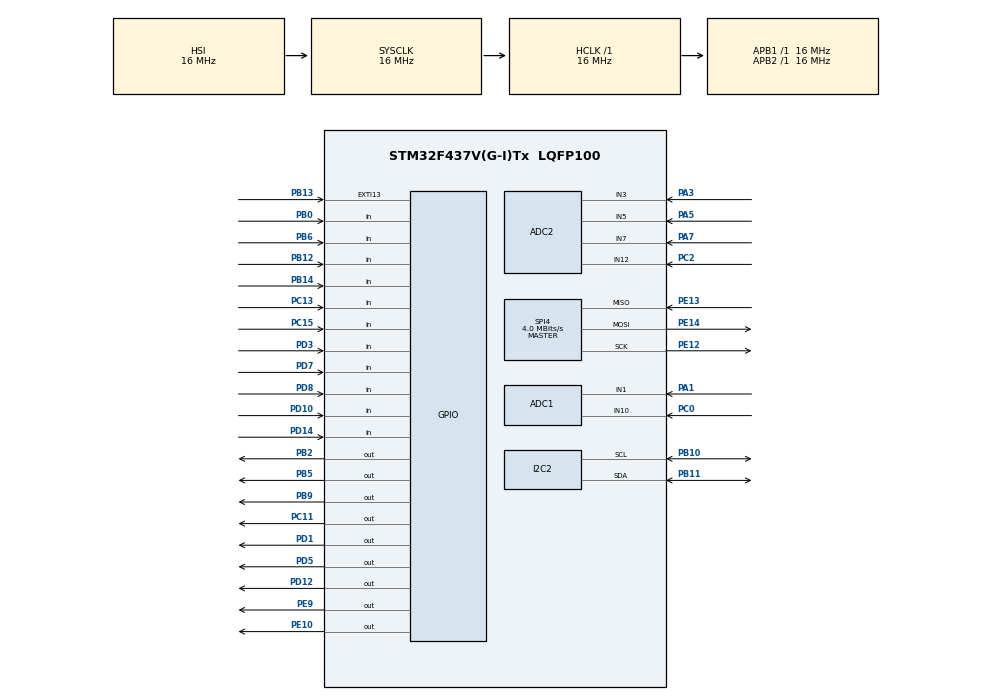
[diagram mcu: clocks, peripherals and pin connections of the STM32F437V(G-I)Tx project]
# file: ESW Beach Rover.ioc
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ADC1.Channel-0\#ChannelRegularConversion=ADC_CHANNEL_1
ADC1.NbrOfConversionFlag=1
ADC1.Rank-0\#ChannelRegularConversion=1
ADC1.SamplingTime-0\#ChannelRegularConversion=ADC_SAMPLETIME_3CYCLES
ADC1.master=1
ADC2.Channel-0\#ChannelRegularConversion=ADC_CHANNEL_3
ADC2.NbrOfConversionFlag=1
ADC2.Rank-0\#ChannelRegularConversion=1
ADC2.SamplingTime-0\#ChannelRegularConversion=ADC_SAMPLETIME_3CYCLES
Mcu.Family=STM32F4
Mcu.Name=STM32F437V(G-I)Tx
Mcu.Package=LQFP100
NVIC.PriorityGroup=NVIC_PRIORITYGROUP_4
PA1.Signal=ADCx_IN1
PA11.Signal=S_TIM1_CH4
PA13.Signal=SYS_JTMS-SWDIO
PA14.Signal=SYS_JTCK-SWCLK
PA15.Signal=S_TIM2_CH1_ETR
PA3.Signal=ADCx_IN3
PA5.Signal=ADCx_IN5
PA7.Signal=ADCx_IN7
PA9.Signal=S_TIM1_CH2
PB0.Signal=GPIO_Input
PB10.Mode=I2C
PB10.Signal=I2C2_SCL
PB11.Mode=I2C
PB11.Signal=I2C2_SDA
PB12.Signal=GPIO_Input
PB13.Signal=GPXTI13
PB14.Signal=GPIO_Input
PB2/BOOT1.Signal=GPIO_Output
PB5.Signal=GPIO_Output
PB6.Signal=GPIO_Input
PB9.Signal=GPIO_Output
PC0.Signal=ADCx_IN10
PC11.Signal=GPIO_Output
PC12.Signal=UART5_TX
PC13.Signal=GPIO_Input
PC15/OSC32_OUT.Signal=GPIO_Input
PC2.Signal=ADCx_IN12
PC6.Signal=S_TIM3_CH1
PC8.Signal=S_TIM3_CH3
PD1.Signal=GPIO_Output
PD10.Signal=GPIO_Input
PD12.Signal=GPIO_Output
PD14.Signal=GPIO_Input
PD2.Signal=UART5_RX
PD3.Signal=GPIO_Input
PD5.Signal=GPIO_Output
PD7.Signal=GPIO_Input
PD8.Signal=GPIO_Input
PE10.Signal=GPIO_Output
PE12.Mode=Full_Duplex_Master
PE12.Signal=SPI4_SCK
PE13.Mode=Full_Duplex_Master
PE13.Signal=SPI4_MISO
PE14.Mode=Full_Duplex_Master
PE14.Signal=SPI4_MOSI
PE9.Signal=GPIO_Output
ProjectManager.HeapSize=0x200
ProjectManager.StackSize=0x400
ProjectManager.TargetToolchain=STM32CubeIDE
RCC.AHBFreq_Value=16000000
RCC.APB1Freq_Value=16000000
RCC.APB2Freq_Value=16000000
RCC.CortexFreq_Value=16000000
RCC.HSE_VALUE=25000000
RCC.HSI_VALUE=16000000
RCC.LSE_VALUE=32768
RCC.SYSCLKFreq_VALUE=16000000
RCC.VCOOutputFreq_Value=192000000
SH.ADCx_IN1.0=ADC1_IN1,IN1
SH.ADCx_IN10.0=ADC1_IN10,IN10
SH.ADCx_IN12.0=ADC2_IN12,IN12
SH.ADCx_IN3.0=ADC2_IN3,IN3
SH.ADCx_IN5.0=ADC2_IN5,IN5
SH.ADCx_IN7.0=ADC2_IN7,IN7
SH.S_TIM1_CH2.0=TIM1_CH2
SH.S_TIM1_CH4.0=TIM1_CH4
SH.S_TIM2_CH1_ETR.0=TIM2_CH1
SH.S_TIM3_CH1.0=TIM3_CH1
SH.S_TIM3_CH3.0=TIM3_CH3
SPI4.BaudRatePrescaler=SPI_BAUDRATEPRESCALER_4
SPI4.CalculateBaudRate=4.0 MBits/s
SPI4.Direction=SPI_DIRECTION_2LINES
SPI4.Mode=SPI_MODE_MASTER
SPI4.VirtualType=VM_MASTER
board=custom

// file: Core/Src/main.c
/* USER CODE BEGIN Header */
/**
  ******************************************************************************
  * @file           : main.c
  * @brief          : Main program body
  ******************************************************************************
  * @attention
  *
  * Copyright (c) 2025 STMicroelectronics.
  * All rights reserved.
  *
  * This software is licensed under terms that can be found in the LICENSE file
  * in the root directory of this software component.
  * If no LICENSE file comes with this software, it is provided AS-IS.
  *
  ******************************************************************************
  */
/* USER CODE END Header */
#include "main.h"

/* USER CODE BEGIN Includes */
#include <string.h>
#include "NRF24.h"
#include "NRF24_reg_addresses.h"
/* USER CODE END Includes */

/* USER CODE BEGIN PD */
#define NRF_CE_HIGH()    HAL_GPIO_WritePin(GPIOE, GPIO_PIN_10, GPIO_PIN_SET);
#define NRF_CE_LOW()     HAL_GPIO_WritePin(GPIOE, GPIO_PIN_10, GPIO_PIN_RESET);

#define NRF_CSN_HIGH()   HAL_GPIO_WritePin(GPIOE, GPIO_PIN_9, GPIO_PIN_SET);
#define NRF_CSN_LOW()    HAL_GPIO_WritePin(GPIOE, GPIO_PIN_9, GPIO_PIN_RESET);

#define PLD_SIZE 32
/* USER CODE END PD */

ADC_HandleTypeDef hadc1;
ADC_HandleTypeDef hadc2;

I2C_HandleTypeDef hi2c2;

SPI_HandleTypeDef hspi4;

void SystemClock_Config(void);
static void MX_GPIO_Init(void);
static void MX_ADC1_Init(void);
static void MX_ADC2_Init(void);
static void MX_I2C2_Init(void);
static void MX_SPI4_Init(void);

int main(void)
{

  /* MCU Configuration--------------------------------------------------------*/

  /* Reset of all peripherals, Initializes the Flash interface and the Systick. */
  HAL_Init();

  /* Configure the system clock */
  SystemClock_Config();

  /* Initialize all configured peripherals */
  MX_GPIO_Init();
  MX_ADC1_Init();
  MX_ADC2_Init();
  MX_I2C2_Init();
  MX_SPI4_Init();

  /* Infinite loop */
  while (1)
  {

  }
}

void SystemClock_Config(void)
{
  RCC_OscInitTypeDef RCC_OscInitStruct = {0};
  RCC_ClkInitTypeDef RCC_ClkInitStruct = {0};

  /** Configure the main internal regulator output voltage
  */
  __HAL_RCC_PWR_CLK_ENABLE();
  __HAL_PWR_VOLTAGESCALING_CONFIG(PWR_REGULATOR_VOLTAGE_SCALE3);

  /** Initializes the RCC Oscillators according to the specified parameters
  * in the RCC_OscInitTypeDef structure.
  */
  RCC_OscInitStruct.OscillatorType = RCC_OSCILLATORTYPE_HSI;
  RCC_OscInitStruct.HSIState = RCC_HSI_ON;
  RCC_OscInitStruct.HSICalibrationValue = RCC_HSICALIBRATION_DEFAULT;
  RCC_OscInitStruct.PLL.PLLState = RCC_PLL_NONE;
  if (HAL_RCC_OscConfig(&RCC_OscInitStruct) != HAL_OK)
  {
    Error_Handler();
  }

  /** Initializes the CPU, AHB and APB buses clocks
  */
  RCC_ClkInitStruct.ClockType = RCC_CLOCKTYPE_HCLK|RCC_CLOCKTYPE_SYSCLK
                              |RCC_CLOCKTYPE_PCLK1|RCC_CLOCKTYPE_PCLK2;
  RCC_ClkInitStruct.SYSCLKSource = RCC_SYSCLKSOURCE_HSI;
  RCC_ClkInitStruct.AHBCLKDivider = RCC_SYSCLK_DIV1;
  RCC_ClkInitStruct.APB1CLKDivider = RCC_HCLK_DIV1;
  RCC_ClkInitStruct.APB2CLKDivider = RCC_HCLK_DIV1;

  if (HAL_RCC_ClockConfig(&RCC_ClkInitStruct, FLASH_LATENCY_0) != HAL_OK)
  {
    Error_Handler();
  }
}

static void MX_ADC1_Init(void)
{

  ADC_ChannelConfTypeDef sConfig = {0};

  /** Configure the global features of the ADC (Clock, Resolution, Data Alignment and number of conversion)
  */
  hadc1.Instance = ADC1;
  hadc1.Init.ClockPrescaler = ADC_CLOCK_SYNC_PCLK_DIV2;
  hadc1.Init.Resolution = ADC_RESOLUTION_12B;
  hadc1.Init.ScanConvMode = DISABLE;
  hadc1.Init.ContinuousConvMode = DISABLE;
  hadc1.Init.DiscontinuousConvMode = DISABLE;
  hadc1.Init.ExternalTrigConvEdge = ADC_EXTERNALTRIGCONVEDGE_NONE;
  hadc1.Init.ExternalTrigConv = ADC_SOFTWARE_START;
  hadc1.Init.DataAlign = ADC_DATAALIGN_RIGHT;
  hadc1.Init.NbrOfConversion = 1;
  hadc1.Init.DMAContinuousRequests = DISABLE;
  hadc1.Init.EOCSelection = ADC_EOC_SINGLE_CONV;
  if (HAL_ADC_Init(&hadc1) != HAL_OK)
  {
    Error_Handler();
  }

  /** Configure for the selected ADC regular channel its corresponding rank in the sequencer and its sample time.
  */
  sConfig.Channel = ADC_CHANNEL_1;
  sConfig.Rank = 1;
  sConfig.SamplingTime = ADC_SAMPLETIME_3CYCLES;
  if (HAL_ADC_ConfigChannel(&hadc1, &sConfig) != HAL_OK)
  {
    Error_Handler();
  }

}

static void MX_ADC2_Init(void)
{

  ADC_ChannelConfTypeDef sConfig = {0};

  /** Configure the global features of the ADC (Clock, Resolution, Data Alignment and number of conversion)
  */
  hadc2.Instance = ADC2;
  hadc2.Init.ClockPrescaler = ADC_CLOCK_SYNC_PCLK_DIV2;
  hadc2.Init.Resolution = ADC_RESOLUTION_12B;
  hadc2.Init.ScanConvMode = DISABLE;
  hadc2.Init.ContinuousConvMode = DISABLE;
  hadc2.Init.DiscontinuousConvMode = DISABLE;
  hadc2.Init.ExternalTrigConvEdge = ADC_EXTERNALTRIGCONVEDGE_NONE;
  hadc2.Init.ExternalTrigConv = ADC_SOFTWARE_START;
  hadc2.Init.DataAlign = ADC_DATAALIGN_RIGHT;
  hadc2.Init.NbrOfConversion = 1;
  hadc2.Init.DMAContinuousRequests = DISABLE;
  hadc2.Init.EOCSelection = ADC_EOC_SINGLE_CONV;
  if (HAL_ADC_Init(&hadc2) != HAL_OK)
  {
    Error_Handler();
  }

  /** Configure for the selected ADC regular channel its corresponding rank in the sequencer and its sample time.
  */
  sConfig.Channel = ADC_CHANNEL_3;
  sConfig.Rank = 1;
  sConfig.SamplingTime = ADC_SAMPLETIME_3CYCLES;
  if (HAL_ADC_ConfigChannel(&hadc2, &sConfig) != HAL_OK)
  {
    Error_Handler();
  }

}

static void MX_I2C2_Init(void)
{

  hi2c2.Instance = I2C2;
  hi2c2.Init.ClockSpeed = 100000;
  hi2c2.Init.DutyCycle = I2C_DUTYCYCLE_2;
  hi2c2.Init.OwnAddress1 = 0;
  hi2c2.Init.AddressingMode = I2C_ADDRESSINGMODE_7BIT;
  hi2c2.Init.DualAddressMode = I2C_DUALADDRESS_DISABLE;
  hi2c2.Init.OwnAddress2 = 0;
  hi2c2.Init.GeneralCallMode = I2C_GENERALCALL_DISABLE;
  hi2c2.Init.NoStretchMode = I2C_NOSTRETCH_DISABLE;
  if (HAL_I2C_Init(&hi2c2) != HAL_OK)
  {
    Error_Handler();
  }

  /** Configure Analogue filter
  */
  if (HAL_I2CEx_ConfigAnalogFilter(&hi2c2, I2C_ANALOGFILTER_ENABLE) != HAL_OK)
  {
    Error_Handler();
  }

  /** Configure Digital filter
  */
  if (HAL_I2CEx_ConfigDigitalFilter(&hi2c2, 0) != HAL_OK)
  {
    Error_Handler();
  }

}

static void MX_SPI4_Init(void)
{

  /* SPI4 parameter configuration*/
  hspi4.Instance = SPI4;
  hspi4.Init.Mode = SPI_MODE_MASTER;
  hspi4.Init.Direction = SPI_DIRECTION_2LINES;
  hspi4.Init.DataSize = SPI_DATASIZE_8BIT;
  hspi4.Init.CLKPolarity = SPI_POLARITY_LOW;
  hspi4.Init.CLKPhase = SPI_PHASE_1EDGE;
  hspi4.Init.NSS = SPI_NSS_SOFT;
  hspi4.Init.BaudRatePrescaler = SPI_BAUDRATEPRESCALER_4;
  hspi4.Init.FirstBit = SPI_FIRSTBIT_MSB;
  hspi4.Init.TIMode = SPI_TIMODE_DISABLE;
  hspi4.Init.CRCCalculation = SPI_CRCCALCULATION_DISABLE;
  hspi4.Init.CRCPolynomial = 10;
  if (HAL_SPI_Init(&hspi4) != HAL_OK)
  {
    Error_Handler();
  }

}

static void MX_GPIO_Init(void)
{
  GPIO_InitTypeDef GPIO_InitStruct = {0};

  /* GPIO Ports Clock Enable */
  __HAL_RCC_GPIOC_CLK_ENABLE();
  __HAL_RCC_GPIOA_CLK_ENABLE();
  __HAL_RCC_GPIOB_CLK_ENABLE();
  __HAL_RCC_GPIOE_CLK_ENABLE();
  __HAL_RCC_GPIOD_CLK_ENABLE();

  /*Configure GPIO pin Output Level */
  HAL_GPIO_WritePin(GPIOB, GPIO_PIN_2|GPIO_PIN_5|GPIO_PIN_9, GPIO_PIN_RESET);

  /*Configure GPIO pin Output Level */
  HAL_GPIO_WritePin(GPIOE, GPIO_PIN_9|GPIO_PIN_10, GPIO_PIN_RESET);

  /*Configure GPIO pin Output Level */
  HAL_GPIO_WritePin(GPIOD, GPIO_PIN_12|GPIO_PIN_1|GPIO_PIN_5, GPIO_PIN_RESET);

  /*Configure GPIO pin Output Level */
  HAL_GPIO_WritePin(GPIOC, GPIO_PIN_11, GPIO_PIN_RESET);

  /*Configure GPIO pins : PC13 PC15 */
  GPIO_InitStruct.Pin = GPIO_PIN_13|GPIO_PIN_15;
  GPIO_InitStruct.Mode = GPIO_MODE_INPUT;
  GPIO_InitStruct.Pull = GPIO_NOPULL;
  HAL_GPIO_Init(GPIOC, &GPIO_InitStruct);

  /*Configure GPIO pins : PB0 PB12 PB13 PB14
                           PB6 */
  GPIO_InitStruct.Pin = GPIO_PIN_0|GPIO_PIN_12|GPIO_PIN_13|GPIO_PIN_14
                          |GPIO_PIN_6;
  GPIO_InitStruct.Mode = GPIO_MODE_INPUT;
  GPIO_InitStruct.Pull = GPIO_NOPULL;
  HAL_GPIO_Init(GPIOB, &GPIO_InitStruct);

  /*Configure GPIO pins : PB2 PB5 PB9 */
  GPIO_InitStruct.Pin = GPIO_PIN_2|GPIO_PIN_5|GPIO_PIN_9;
  GPIO_InitStruct.Mode = GPIO_MODE_OUTPUT_PP;
  GPIO_InitStruct.Pull = GPIO_NOPULL;
  GPIO_InitStruct.Speed = GPIO_SPEED_FREQ_LOW;
  HAL_GPIO_Init(GPIOB, &GPIO_InitStruct);

  /*Configure GPIO pins : PE9 PE10 */
  GPIO_InitStruct.Pin = GPIO_PIN_9|GPIO_PIN_10;
  GPIO_InitStruct.Mode = GPIO_MODE_OUTPUT_PP;
  GPIO_InitStruct.Pull = GPIO_NOPULL;
  GPIO_InitStruct.Speed = GPIO_SPEED_FREQ_LOW;
  HAL_GPIO_Init(GPIOE, &GPIO_InitStruct);

  /*Configure GPIO pins : PD8 PD10 PD14 PD3
                           PD7 */
  GPIO_InitStruct.Pin = GPIO_PIN_8|GPIO_PIN_10|GPIO_PIN_14|GPIO_PIN_3
                          |GPIO_PIN_7;
  GPIO_InitStruct.Mode = GPIO_MODE_INPUT;
  GPIO_InitStruct.Pull = GPIO_NOPULL;
  HAL_GPIO_Init(GPIOD, &GPIO_InitStruct);

  /*Configure GPIO pins : PD12 PD1 PD5 */
  GPIO_InitStruct.Pin = GPIO_PIN_12|GPIO_PIN_1|GPIO_PIN_5;
  GPIO_InitStruct.Mode = GPIO_MODE_OUTPUT_PP;
  GPIO_InitStruct.Pull = GPIO_NOPULL;
  GPIO_InitStruct.Speed = GPIO_SPEED_FREQ_LOW;
  HAL_GPIO_Init(GPIOD, &GPIO_InitStruct);

  /*Configure GPIO pins : PC6 PC8 */
  GPIO_InitStruct.Pin = GPIO_PIN_6|GPIO_PIN_8;
  GPIO_InitStruct.Mode = GPIO_MODE_AF_PP;
  GPIO_InitStruct.Pull = GPIO_NOPULL;
  GPIO_InitStruct.Speed = GPIO_SPEED_FREQ_LOW;
  GPIO_InitStruct.Alternate = GPIO_AF2_TIM3;
  HAL_GPIO_Init(GPIOC, &GPIO_InitStruct);

  /*Configure GPIO pins : PA9 PA11 */
  GPIO_InitStruct.Pin = GPIO_PIN_9|GPIO_PIN_11;
  GPIO_InitStruct.Mode = GPIO_MODE_AF_PP;
  GPIO_InitStruct.Pull = GPIO_NOPULL;
  GPIO_InitStruct.Speed = GPIO_SPEED_FREQ_LOW;
  GPIO_InitStruct.Alternate = GPIO_AF1_TIM1;
  HAL_GPIO_Init(GPIOA, &GPIO_InitStruct);

  /*Configure GPIO pin : PA15 */
  GPIO_InitStruct.Pin = GPIO_PIN_15;
  GPIO_InitStruct.Mode = GPIO_MODE_AF_PP;
  GPIO_InitStruct.Pull = GPIO_NOPULL;
  GPIO_InitStruct.Speed = GPIO_SPEED_FREQ_LOW;
  GPIO_InitStruct.Alternate = GPIO_AF1_TIM2;
  HAL_GPIO_Init(GPIOA, &GPIO_InitStruct);

  /*Configure GPIO pin : PC11 */
  GPIO_InitStruct.Pin = GPIO_PIN_11;
  GPIO_InitStruct.Mode = GPIO_MODE_OUTPUT_PP;
  GPIO_InitStruct.Pull = GPIO_NOPULL;
  GPIO_InitStruct.Speed = GPIO_SPEED_FREQ_LOW;
  HAL_GPIO_Init(GPIOC, &GPIO_InitStruct);

  /*Configure GPIO pin : PC12 */
  GPIO_InitStruct.Pin = GPIO_PIN_12;
  GPIO_InitStruct.Mode = GPIO_MODE_AF_PP;
  GPIO_InitStruct.Pull = GPIO_NOPULL;
  GPIO_InitStruct.Speed = GPIO_SPEED_FREQ_VERY_HIGH;
  GPIO_InitStruct.Alternate = GPIO_AF8_UART5;
  HAL_GPIO_Init(GPIOC, &GPIO_InitStruct);

  /*Configure GPIO pin : PD2 */
  GPIO_InitStruct.Pin = GPIO_PIN_2;
  GPIO_InitStruct.Mode = GPIO_MODE_AF_PP;
  GPIO_InitStruct.Pull = GPIO_NOPULL;
  GPIO_InitStruct.Speed = GPIO_SPEED_FREQ_VERY_HIGH;
  GPIO_InitStruct.Alternate = GPIO_AF8_UART5;
  HAL_GPIO_Init(GPIOD, &GPIO_InitStruct);

}

void Error_Handler(void)
{
  __disable_irq();
  while (1)
  {
  }
}
